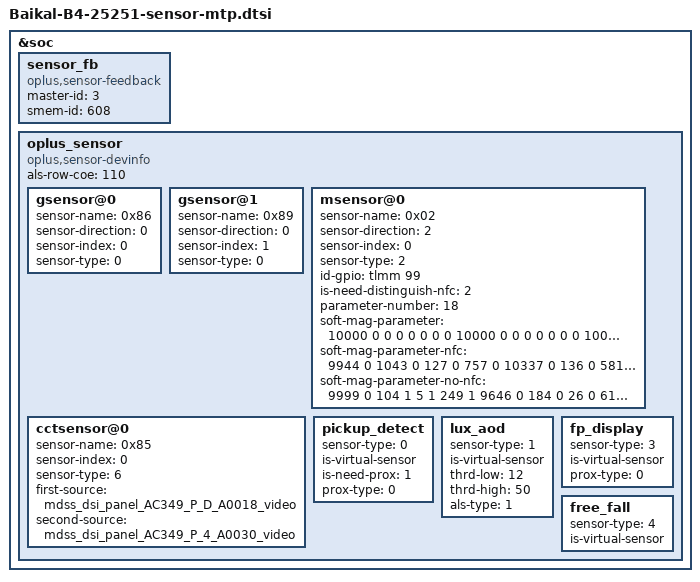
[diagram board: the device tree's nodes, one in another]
&soc {
	sensor_fb: sensor_fb {
		compatible = "oplus,sensor-feedback";
		master-id  = <3>;
		smem-id    = <608>;
	};
	oplus_sensor {
			compatible = "oplus,sensor-devinfo";
			als-row-coe = <110>;
			/*enum {LSM6DSM = 0x01, BMI160 = 0x02, LSM6DS3 = 0x04, BMI260 = 0x08};*/
			gsensor@0 {
					sensor-name = <0x86>;//STK83xx
					sensor-direction = <0>;
					sensor-index = <0>;//source num
					sensor-type = <0>;//OPPO_ACCEL
			};
			gsensor@1 {
					sensor-name = <0x89>;//BMA510
					sensor-direction = <0>;
					sensor-index = <1>;//source num
					sensor-type = <0>;//OPPO_ACCEL
			};
			/* enum {AKM0991X = 0x01, MMC5603 = 0x02, MXG4300 = 0x04};*/
			msensor@0 {
					sensor-name = <0x02>;//MMC5603
					sensor-direction = <2>;
					sensor-index = <0>;
					sensor-type = <2>;//OPLUS_MAG
					id-gpio = <&tlmm 99 0x00>;
					is-need-distinguish-nfc = <2>;
					parameter-number= <18>;
					soft-mag-parameter = <10000 0 0 0 0 0 0 0 10000 0 0 0 0 0 0 0 10000 0>;
					soft-mag-parameter-nfc = <9944 0 1043 0 127 0 757 0 10337 0 136 0 581 0 273 1 11246 0>;
					soft-mag-parameter-no-nfc = <9999 0 104 1 5 1 249 1 9646 0 184 0 26 0 61 1 10601 0>;//e00 sign e01 sign...
			};
			cctsensor@0 {
				sensor-name = <0x85>;            // stk63701
				sensor-index = <0>;              // source num
				sensor-type = <6>;               // OPLUS_CCT
				first-source = "mdss_dsi_panel_AC349_P_D_A0018_video";
				second-source = "mdss_dsi_panel_AC349_P_4_A0030_video";
		};
			/*virtual sensor
			enum sensor_algo_id {
					OPLUS_PICKUP_DETECT,
					OPLUS_LUX_AOD,
					OPLUS_TP_GESTURE,
					OPLUS_FP_DISPLAY,
					OPLUS_FREE_FALL,
					OPLUS_CAMERA_PROTECT,
					SENSOR_ALGO_NUM
			}*/
			pickup_detect {
					sensor-type = <0>; //OPLUS_PICKUP_DETECT
					is-virtual-sensor;
					is-need-prox = <1>;
					prox-type = <0>; // 0 - proximity; 1 - proximity_fake
			};
			lux_aod {
					sensor-type = <1>; //OPLUS_LUX_AOD
					is-virtual-sensor;
					thrd-low = <12>;
					thrd-high = <50>;
					als-type = <1>; // 0 - wise_light; 1 - ambient_light
			};
			fp_display {
					sensor-type = <3>; //OPLUS_FP_DISPLAY
					is-virtual-sensor;
					prox-type = <0>; // 0 - proximity; 1 - proximity_fake
			};
			free_fall {
					sensor-type = <4>; //OPLUS_FREE_FALL
					is-virtual-sensor;
			};
	};
};
